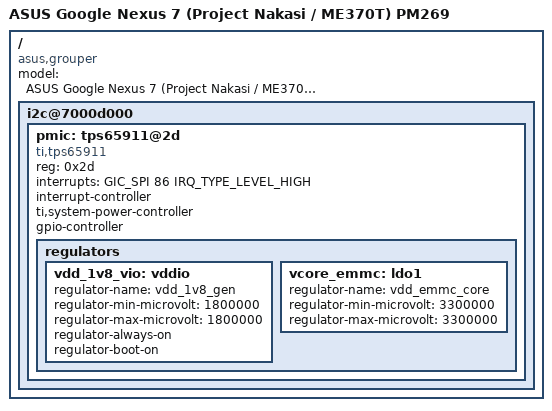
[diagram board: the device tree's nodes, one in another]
// SPDX-License-Identifier: GPL-2.0
/dts-v1/;

#include "tegra30-asus-grouper-common.dtsi"

/ {
	model = "ASUS Google Nexus 7 (Project Nakasi / ME370T) PM269";
	compatible = "asus,grouper", "nvidia,tegra30";

	i2c@7000d000 {
		/* Texas Instruments TPS659110 PMIC */
		pmic: tps65911@2d {
			compatible = "ti,tps65911";
			reg = <0x2d>;

			interrupts = <GIC_SPI 86 IRQ_TYPE_LEVEL_HIGH>;
			#interrupt-cells = <2>;
			interrupt-controller;

			ti,system-power-controller;

			#gpio-cells = <2>;
			gpio-controller;

			regulators {
				vdd_1v8_vio: vddio {
					regulator-name = "vdd_1v8_gen";
					regulator-min-microvolt = <1800000>;
					regulator-max-microvolt = <1800000>;
					regulator-always-on;
					regulator-boot-on;
				};

				/* eMMC VDD */
				vcore_emmc: ldo1 {
					regulator-name = "vdd_emmc_core";
					regulator-min-microvolt = <3300000>;
					regulator-max-microvolt = <3300000>;
				};
			};
		};
	};
};
